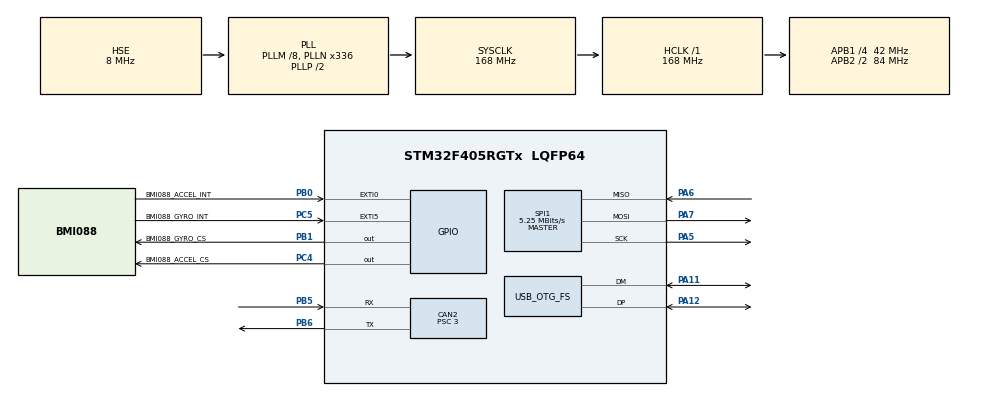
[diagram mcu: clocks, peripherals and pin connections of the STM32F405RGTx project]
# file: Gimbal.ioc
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CAN2.BS1=CAN_BS1_10TQ
CAN2.BS2=CAN_BS2_3TQ
CAN2.CalculateBaudRate=1000000
CAN2.CalculateTimeBit=1000
CAN2.CalculateTimeQuantum=71.42857142857143
CAN2.NART=ENABLE
CAN2.Prescaler=3
Dma.Request0=SPI1_RX
Dma.Request1=SPI1_TX
Dma.SPI1_RX.0.Direction=DMA_PERIPH_TO_MEMORY
Dma.SPI1_RX.0.FIFOMode=DMA_FIFOMODE_DISABLE
Dma.SPI1_RX.0.Instance=DMA2_Stream0
Dma.SPI1_RX.0.MemDataAlignment=DMA_MDATAALIGN_BYTE
Dma.SPI1_RX.0.MemInc=DMA_MINC_ENABLE
Dma.SPI1_RX.0.Mode=DMA_NORMAL
Dma.SPI1_RX.0.PeriphDataAlignment=DMA_PDATAALIGN_BYTE
Dma.SPI1_RX.0.PeriphInc=DMA_PINC_DISABLE
Dma.SPI1_RX.0.Priority=DMA_PRIORITY_VERY_HIGH
Dma.SPI1_TX.1.Direction=DMA_MEMORY_TO_PERIPH
Dma.SPI1_TX.1.FIFOMode=DMA_FIFOMODE_DISABLE
Dma.SPI1_TX.1.Instance=DMA2_Stream3
Dma.SPI1_TX.1.MemDataAlignment=DMA_MDATAALIGN_BYTE
Dma.SPI1_TX.1.MemInc=DMA_MINC_ENABLE
Dma.SPI1_TX.1.Mode=DMA_NORMAL
Dma.SPI1_TX.1.PeriphDataAlignment=DMA_PDATAALIGN_BYTE
Dma.SPI1_TX.1.PeriphInc=DMA_PINC_DISABLE
Dma.SPI1_TX.1.Priority=DMA_PRIORITY_VERY_HIGH
FREERTOS.Tasks01=robotTask,24,512,StartRobotTask,Default,NULL,Dynamic,NULL,NULL;insTask,32,1024,StartINSTask,As external,NULL,Dynamic,NULL,NULL;motorTask,24,256,StartMotorTask,As external,NULL,Dynamic,NULL,NULL;daemonTask,24,256,StartDaemonTask,As external,NULL,Dynamic,NULL,NULL
Mcu.Family=STM32F4
Mcu.Name=STM32F405RGTx
Mcu.Package=LQFP64
NVIC.CAN2_RX0_IRQn=true\:5\:0\:false\:false\:true\:true\:true\:true\:true
NVIC.DMA2_Stream0_IRQn=true\:5\:0\:false\:false\:true\:true\:false\:true\:true
NVIC.DMA2_Stream3_IRQn=true\:5\:0\:false\:false\:true\:true\:false\:true\:true
NVIC.EXTI0_IRQn=true\:5\:0\:true\:false\:true\:true\:true\:true\:true
NVIC.EXTI9_5_IRQn=true\:5\:0\:true\:false\:true\:true\:true\:true\:true
NVIC.OTG_FS_IRQn=true\:5\:0\:false\:false\:true\:true\:false\:true\:true
NVIC.PriorityGroup=NVIC_PRIORITYGROUP_4
NVIC.TIM6_DAC_IRQn=true\:15\:0\:false\:false\:true\:false\:false\:true\:true
NVIC.TimeBase=TIM6_DAC_IRQn
NVIC.TimeBaseIP=TIM6
PA11.Mode=Device_Only
PA11.Signal=USB_OTG_FS_DM
PA12.Mode=Device_Only
PA12.Signal=USB_OTG_FS_DP
PA13.Mode=Serial_Wire
PA13.Signal=SYS_JTMS-SWDIO
PA14.Mode=Serial_Wire
PA14.Signal=SYS_JTCK-SWCLK
PA5.Mode=Full_Duplex_Master
PA5.Signal=SPI1_SCK
PA6.Mode=Full_Duplex_Master
PA6.Signal=SPI1_MISO
PA7.Mode=Full_Duplex_Master
PA7.Signal=SPI1_MOSI
PB0.GPIO_Label=BMI088_ACCEL_INT
PB0.Signal=GPXTI0
PB1.GPIO_Label=BMI088_GYRO_CS
PB1.GPIO_Speed=GPIO_SPEED_FREQ_HIGH
PB1.PinState=GPIO_PIN_SET
PB1.Signal=GPIO_Output
PB5.Mode=CAN_Activate
PB5.Signal=CAN2_RX
PB6.Mode=CAN_Activate
PB6.Signal=CAN2_TX
PC4.GPIO_Label=BMI088_ACCEL_CS
PC4.GPIO_Speed=GPIO_SPEED_FREQ_HIGH
PC4.PinState=GPIO_PIN_SET
PC4.Signal=GPIO_Output
PC5.GPIO_Label=BMI088_GYRO_INT
PC5.Signal=GPXTI5
PH0-OSC_IN.Mode=HSE-External-Oscillator
PH0-OSC_IN.Signal=RCC_OSC_IN
PH1-OSC_OUT.Mode=HSE-External-Oscillator
PH1-OSC_OUT.Signal=RCC_OSC_OUT
ProjectManager.HeapSize=0x200
ProjectManager.StackSize=0x400
ProjectManager.TargetToolchain=CMake
RCC.48MHZClocksFreq_Value=48000000
RCC.AHBFreq_Value=168000000
RCC.APB1CLKDivider=RCC_HCLK_DIV4
RCC.APB1Freq_Value=42000000
RCC.APB1TimFreq_Value=84000000
RCC.APB2CLKDivider=RCC_HCLK_DIV2
RCC.APB2Freq_Value=84000000
RCC.APB2TimFreq_Value=168000000
RCC.CortexFreq_Value=168000000
RCC.EnbaleCSS=true
RCC.HCLKFreq_Value=168000000
RCC.HSE_VALUE=8000000
RCC.HSI_VALUE=16000000
RCC.LSE_VALUE=32768
RCC.PLLM=8
RCC.PLLN=336
RCC.PLLQ=7
RCC.SYSCLKFreq_VALUE=168000000
RCC.SYSCLKSource=RCC_SYSCLKSOURCE_PLLCLK
RCC.VCOOutputFreq_Value=336000000
SPI1.BaudRatePrescaler=SPI_BAUDRATEPRESCALER_16
SPI1.CalculateBaudRate=5.25 MBits/s
SPI1.Direction=SPI_DIRECTION_2LINES
SPI1.Mode=SPI_MODE_MASTER
SPI1.VirtualType=VM_MASTER
USB_DEVICE.CLASS_NAME_FS=CDC
USB_DEVICE.VirtualMode-CDC_FS=Cdc
USB_DEVICE.VirtualModeFS=Cdc_FS
USB_OTG_FS.VirtualMode=Device_Only
VP_FREERTOS_VS_CMSIS_V2.Mode=CMSIS_V2
VP_SYS_VS_tim6.Mode=TIM6
VP_USB_DEVICE_VS_USB_DEVICE_CDC_FS.Mode=CDC_FS
board=custom

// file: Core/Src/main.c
/* USER CODE BEGIN Header */
/**
  ******************************************************************************
  * @file           : main.c
  * @brief          : Main program body
  ******************************************************************************
  * @attention
  *
  * Copyright (c) 2026 STMicroelectronics.
  * All rights reserved.
  *
  * This software is licensed under terms that can be found in the LICENSE file
  * in the root directory of this software component.
  * If no LICENSE file comes with this software, it is provided AS-IS.
  *
  ******************************************************************************
  */
/* USER CODE END Header */
#include "main.h"
#include "cmsis_os.h"
#include "can.h"
#include "dma.h"
#include "spi.h"
#include "usb_device.h"
#include "gpio.h"

/* USER CODE BEGIN Includes */
#include "bsp_dwt.h"

/* USER CODE END Includes */

void SystemClock_Config(void);
void MX_FREERTOS_Init(void);

int main(void)
{

  /* MCU Configuration--------------------------------------------------------*/

  /* Reset of all peripherals, Initializes the Flash interface and the Systick. */
  HAL_Init();

  /* Configure the system clock */
  SystemClock_Config();

  /* USER CODE BEGIN SysInit */
  DWT_Init(HAL_RCC_GetHCLKFreq() / 1000000U);

  /* USER CODE END SysInit */

  /* Initialize all configured peripherals */
  MX_GPIO_Init();
  MX_DMA_Init();
  MX_SPI1_Init();
  MX_CAN2_Init();
  /* USER CODE BEGIN 2 */
  MX_USB_DEVICE_Init();

  /* USER CODE END 2 */

  /* Init scheduler */
  osKernelInitialize();  /* Call init function for freertos objects (in cmsis_os2.c) */
  MX_FREERTOS_Init();

  /* Start scheduler */
  osKernelStart();

  /* We should never get here as control is now taken by the scheduler */

  /* Infinite loop */
  while (1)
  {

  }
}

void SystemClock_Config(void)
{
  RCC_OscInitTypeDef RCC_OscInitStruct = {0};
  RCC_ClkInitTypeDef RCC_ClkInitStruct = {0};

  /** Configure the main internal regulator output voltage
  */
  __HAL_RCC_PWR_CLK_ENABLE();
  __HAL_PWR_VOLTAGESCALING_CONFIG(PWR_REGULATOR_VOLTAGE_SCALE1);

  /** Initializes the RCC Oscillators according to the specified parameters
  * in the RCC_OscInitTypeDef structure.
  */
  RCC_OscInitStruct.OscillatorType = RCC_OSCILLATORTYPE_HSE;
  RCC_OscInitStruct.HSEState = RCC_HSE_ON;
  RCC_OscInitStruct.PLL.PLLState = RCC_PLL_ON;
  RCC_OscInitStruct.PLL.PLLSource = RCC_PLLSOURCE_HSE;
  RCC_OscInitStruct.PLL.PLLM = 8;
  RCC_OscInitStruct.PLL.PLLN = 336;
  RCC_OscInitStruct.PLL.PLLP = RCC_PLLP_DIV2;
  RCC_OscInitStruct.PLL.PLLQ = 7;
  if (HAL_RCC_OscConfig(&RCC_OscInitStruct) != HAL_OK)
  {
    Error_Handler();
  }

  /** Initializes the CPU, AHB and APB buses clocks
  */
  RCC_ClkInitStruct.ClockType = RCC_CLOCKTYPE_HCLK|RCC_CLOCKTYPE_SYSCLK
                              |RCC_CLOCKTYPE_PCLK1|RCC_CLOCKTYPE_PCLK2;
  RCC_ClkInitStruct.SYSCLKSource = RCC_SYSCLKSOURCE_PLLCLK;
  RCC_ClkInitStruct.AHBCLKDivider = RCC_SYSCLK_DIV1;
  RCC_ClkInitStruct.APB1CLKDivider = RCC_HCLK_DIV4;
  RCC_ClkInitStruct.APB2CLKDivider = RCC_HCLK_DIV2;

  if (HAL_RCC_ClockConfig(&RCC_ClkInitStruct, FLASH_LATENCY_5) != HAL_OK)
  {
    Error_Handler();
  }

  /** Enables the Clock Security System
  */
  HAL_RCC_EnableCSS();
}

void HAL_TIM_PeriodElapsedCallback(TIM_HandleTypeDef *htim)
{
  if (htim->Instance == TIM6)
  {
    HAL_IncTick();
  }
}

void Error_Handler(void)
{
  __disable_irq();
  while (1)
  {
  }
}

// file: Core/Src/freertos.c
/* USER CODE BEGIN Header */
/**
  ******************************************************************************
  * File Name          : freertos.c
  * Description        : Code for freertos applications
  ******************************************************************************
  * @attention
  *
  * Copyright (c) 2026 STMicroelectronics.
  * All rights reserved.
  *
  * This software is licensed under terms that can be found in the LICENSE file
  * in the root directory of this software component.
  * If no LICENSE file comes with this software, it is provided AS-IS.
  *
  ******************************************************************************
  */
/* USER CODE END Header */

#include "FreeRTOS.h"
#include "task.h"
#include "main.h"
#include "cmsis_os.h"

/* USER CODE BEGIN Includes */
#include "robot.h"
#include "robot_def.h"

/* USER CODE END Includes */

/* Definitions for robotTask */
osThreadId_t robotTaskHandle;
const osThreadAttr_t robotTask_attributes = {
  .name = "robotTask",
  .stack_size = 512 * 4,
  .priority = (osPriority_t) osPriorityNormal,
};
/* Definitions for insTask */
osThreadId_t insTaskHandle;
const osThreadAttr_t insTask_attributes = {
  .name = "insTask",
  .stack_size = 1024 * 4,
  .priority = (osPriority_t) osPriorityAboveNormal,
};
/* Definitions for motorTask */
osThreadId_t motorTaskHandle;
const osThreadAttr_t motorTask_attributes = {
  .name = "motorTask",
  .stack_size = 256 * 4,
  .priority = (osPriority_t) osPriorityNormal,
};
/* Definitions for daemonTask */
osThreadId_t daemonTaskHandle;
const osThreadAttr_t daemonTask_attributes = {
  .name = "daemonTask",
  .stack_size = 256 * 4,
  .priority = (osPriority_t) osPriorityNormal,
};

void StartRobotTask(void *argument);
extern void StartINSTask(void *argument);
extern void StartMotorTask(void *argument);
extern void StartDaemonTask(void *argument);

void MX_FREERTOS_Init(void); /* (MISRA C 2004 rule 8.1) */

void MX_FREERTOS_Init(void) {
  /* USER CODE BEGIN Init */
  // 调度器启动前完成一次性业务初始化; 任务本体只负责周期运行
#if IMU_ONLY_BRINGUP_ENABLE
#else
  RobotInit();
#endif

  /* USER CODE END Init */

  /* Create the thread(s) */
#if !IMU_ONLY_BRINGUP_ENABLE
  /* creation of robotTask */
  robotTaskHandle = osThreadNew(StartRobotTask, NULL, &robotTask_attributes);
#endif

  /* creation of insTask */
  insTaskHandle = osThreadNew(StartINSTask, NULL, &insTask_attributes);

#if !IMU_ONLY_BRINGUP_ENABLE
  /* creation of motorTask */
  motorTaskHandle = osThreadNew(StartMotorTask, NULL, &motorTask_attributes);
#endif

  /* creation of daemonTask */
  daemonTaskHandle = osThreadNew(StartDaemonTask, NULL, &daemonTask_attributes);

}

void StartRobotTask(void *argument)
{
  /* USER CODE BEGIN StartRobotTask */
  // robotTask 周期: 1ms
  // 职责: 更新应用层状态机、扫描目标和 IMU 反馈到电机控制链路
  for(;;)
  {
    RobotTask();
    osDelay(1);
  }
  /* USER CODE END StartRobotTask */
}
